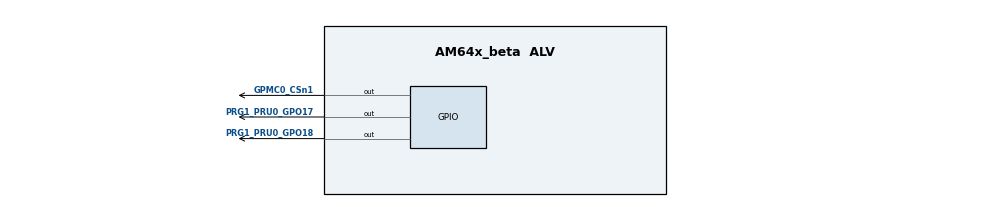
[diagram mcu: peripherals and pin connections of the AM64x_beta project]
/**
 * @cliArgs --device "AM64x_beta" --package "ALV" --part "Default" --context "r5fss0-0" --product "MCU_PLUS_SDK_AM64x@08.03.00"
 * @versions {"tool":"1.13.0+2553"}
 */

/**
 * Import the modules used in this configuration.
 */
const gpio       = scripting.addModule("/drivers/gpio/gpio", {}, false);
const gpio1      = gpio.addInstance();
const gpio2      = gpio.addInstance();
const gpio3      = gpio.addInstance();
const i2c        = scripting.addModule("/drivers/i2c/i2c", {}, false);
const i2c1       = i2c.addInstance();
const pruicss    = scripting.addModule("/drivers/pruicss/pruicss", {}, false);
const pruicss1   = pruicss.addInstance();
const udma       = scripting.addModule("/drivers/udma/udma", {}, false);
const udma1      = udma.addInstance();
const debug_log  = scripting.addModule("/kernel/dpl/debug_log");
const mpu_armv7  = scripting.addModule("/kernel/dpl/mpu_armv7", {}, false);
const mpu_armv71 = mpu_armv7.addInstance();
const mpu_armv72 = mpu_armv7.addInstance();
const mpu_armv73 = mpu_armv7.addInstance();
const mpu_armv74 = mpu_armv7.addInstance();
const mpu_armv75 = mpu_armv7.addInstance();
const mpu_armv76 = mpu_armv7.addInstance();
const hdsl       = scripting.addModule("/motor_control/position_sense/hdsl", {}, false);
const hdsl1      = hdsl.addInstance();

/**
 * Write custom configuration values to the imported modules.
 */
gpio1.$name                = "CONFIG_GPIO0";
gpio1.pinDir               = "OUTPUT";
gpio1.GPIO.gpioPin.rx      = false;
gpio1.GPIO.gpioPin.$assign = "GPMC0_CSn1";

gpio2.$name                = "CONFIG_GPIO_COPY";
gpio2.GPIO.gpioPin.$assign = "PRG1_PRU0_GPO17";

gpio3.$name                = "CONFIG_GPIO_TEST_COPY";
gpio3.GPIO.gpioPin.$assign = "PRG1_PRU0_GPO18";
i2c1.$name       = "CONFIG_I2C0";
i2c1.I2C.$assign = "I2C1";

pruicss1.$name    = "CONFIG_PRU_ICSS1";
pruicss1.instance = "ICSSG1";

udma1.$name                                     = "CONFIG_UDMA0";
udma1.udmaBlkCopyChannel.create(1);
udma1.udmaBlkCopyChannel[0].$name               = "CONFIG_UDMA_BLKCOPY_CH0";
udma1.udmaBlkCopyChannel[0].intrEnable          = true;
udma1.udmaBlkCopyChannel[0].transferCallbackFxn = "App_udmaEventCb";

debug_log.enableUartLog        = true;
debug_log.enableCssLog         = false;
debug_log.uartLog.$name        = "CONFIG_UART0";
debug_log.uartLog.UART.$assign = "USART0";

mpu_armv71.$name             = "CONFIG_MPU_REGION0";
mpu_armv71.size              = 31;
mpu_armv71.attributes        = "Device";
mpu_armv71.accessPermissions = "Supervisor RD+WR, User RD";
mpu_armv71.allowExecute      = false;

mpu_armv72.$name             = "CONFIG_MPU_REGION1";
mpu_armv72.size              = 15;
mpu_armv72.accessPermissions = "Supervisor RD+WR, User RD";

mpu_armv73.$name             = "CONFIG_MPU_REGION2";
mpu_armv73.baseAddr          = 0x41010000;
mpu_armv73.size              = 15;
mpu_armv73.accessPermissions = "Supervisor RD+WR, User RD";

mpu_armv74.$name             = "CONFIG_MPU_REGION3";
mpu_armv74.accessPermissions = "Supervisor RD+WR, User RD";
mpu_armv74.baseAddr          = 0x70000000;
mpu_armv74.size              = 21;

mpu_armv75.$name             = "CONFIG_MPU_REGION4";
mpu_armv75.baseAddr          = 0x60000000;
mpu_armv75.size              = 28;
mpu_armv75.accessPermissions = "Supervisor RD, User RD";

mpu_armv76.$name    = "CONFIG_MPU_REGION5";
mpu_armv76.baseAddr = 0x80000000;
mpu_armv76.size     = 31;

hdsl1.$name                  = "CONFIG_HDSL0";
hdsl1.PRU_ICSSG0_PRU.$assign = "PRU_ICSSG0_PRU1";

const pruicss2 = pruicss.addInstance({}, false);
pruicss2.$name = "CONFIG_PRU_ICSS0";
hdsl1.pru      = pruicss2;

/**
 * Pinmux solution for unlocked pins/peripherals. This ensures that minor changes to the automatic solver in a future
 * version of the tool will not impact the pinmux you originally saw.  These lines can be completely deleted in order to
 * re-solve from scratch.
 */
gpio1.GPIO.$suggestSolution                 = "GPIO0";
gpio2.GPIO.$suggestSolution                 = "GPIO0";
gpio3.GPIO.$suggestSolution                 = "GPIO0";
i2c1.I2C.SCL.$suggestSolution               = "I2C1_SCL";
i2c1.I2C.SDA.$suggestSolution               = "I2C1_SDA";
debug_log.uartLog.UART.RXD.$suggestSolution = "UART0_RXD";
debug_log.uartLog.UART.TXD.$suggestSolution = "UART0_TXD";
hdsl1.PRU_ICSSG0_PRU.GPO2.$suggestSolution  = "PRG0_PRU1_GPO2";
hdsl1.PRU_ICSSG0_PRU.GPO1.$suggestSolution  = "PRG0_PRU1_GPO1";
hdsl1.PRU_ICSSG0_PRU.GPO0.$suggestSolution  = "PRG0_PRU1_GPO0";
hdsl1.PRU_ICSSG0_PRU.GPI13.$suggestSolution = "PRG0_PRU1_GPO13";
hdsl1.PRU_ICSSG0_PRU.GPO5.$suggestSolution  = "PRG0_PRU1_GPO5";
hdsl1.PRU_ICSSG0_PRU.GPO4.$suggestSolution  = "PRG0_PRU1_GPO4";
hdsl1.PRU_ICSSG0_PRU.GPO3.$suggestSolution  = "PRG0_PRU1_GPO3";
hdsl1.PRU_ICSSG0_PRU.GPI14.$suggestSolution = "PRG0_PRU1_GPO14";
hdsl1.PRU_ICSSG0_PRU.GPO8.$suggestSolution  = "PRG0_PRU1_GPO8";
hdsl1.PRU_ICSSG0_PRU.GPO12.$suggestSolution = "PRG0_PRU1_GPO12";
hdsl1.PRU_ICSSG0_PRU.GPO6.$suggestSolution  = "PRG0_PRU1_GPO6";
hdsl1.PRU_ICSSG0_PRU.GPI11.$suggestSolution = "PRG0_PRU1_GPO11";
